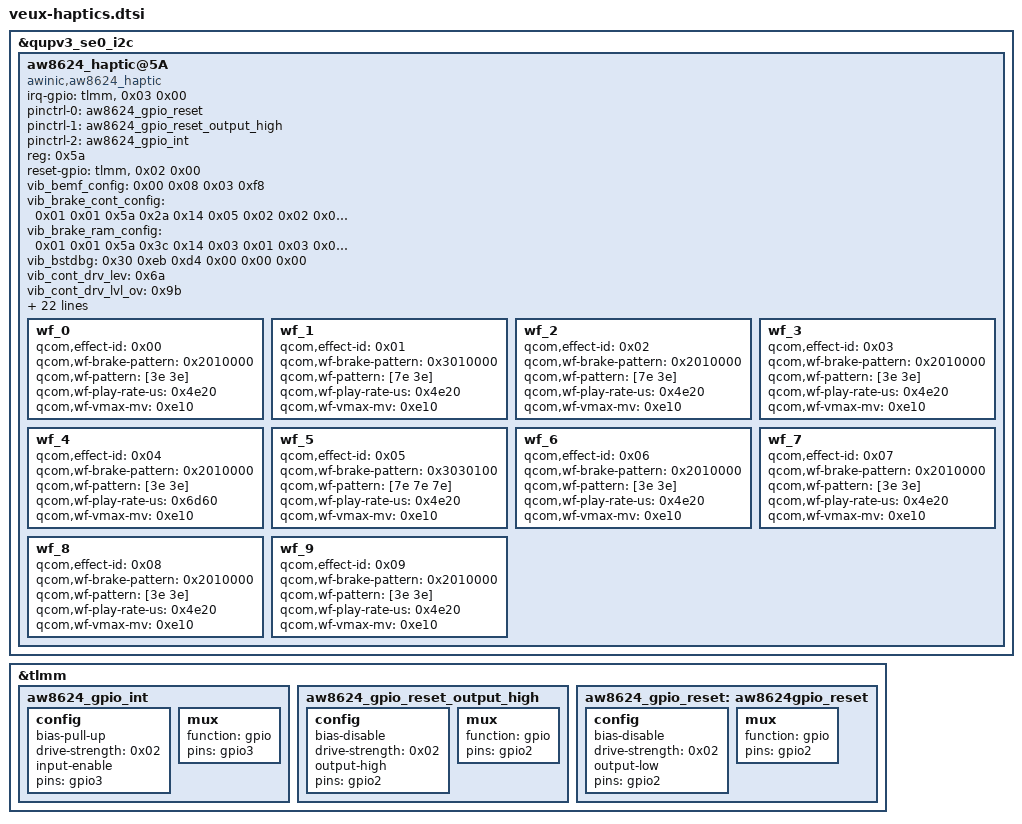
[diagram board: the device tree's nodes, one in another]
/* Xiaomi Poco X4 Pro 5G (veux) - Haptics Subsystem */

/* Fragment 49 -> &qupv3_se0_i2c */
&qupv3_se0_i2c {
	status = "ok";

	/* AWINIC AW8624 high-voltage LRA haptic motor driver at I2C address 0x5a */
		aw8624_haptic@5A {
		compatible = "awinic,aw8624_haptic";
		irq-gpio = <&tlmm>, <0x03 0x00>;
		pinctrl-0 = <&aw8624_gpio_reset>;
		pinctrl-1 = <&aw8624_gpio_reset_output_high>;
		pinctrl-2 = <&aw8624_gpio_int>;
		pinctrl-names = "aw8624_reset_reset", "aw8624_reset_active", "aw8624_interrupt_active";
		reg = <0x5a>;
		reset-gpio = <&tlmm>, <0x02 0x00>;
		vib_bemf_config = <0x00 0x08 0x03 0xf8>;
		vib_brake_cont_config = <0x01 0x01 0x5a 0x2a 0x14 0x05 0x02 0x02 0x00 0x00 0x00 0x00 0x00 0x00 0x00 0x00 0x00 0x00 0x00 0x00 0x00 0x00 0x00 0x00>;
		vib_brake_ram_config = <0x01 0x01 0x5a 0x3c 0x14 0x03 0x01 0x03 0x01 0x01 0x5a 0x3c 0x1e 0x05 0x01 0x03 0x00 0x00 0x32 0x28 0x19 0x00 0x05 0x03>;
		vib_bstdbg = <0x30 0xeb 0xd4 0x00 0x00 0x00>;
		vib_cont_drv_lev = <0x6a>;
		vib_cont_drv_lvl_ov = <0x9b>;
		vib_cont_num_brk = <0x03>;
		vib_cont_td = <0xf06c>;
		vib_cont_zc_thr = <0x8f8>;
		vib_duration_time = <0x0f 0x3c 0x00 0x00 0x00>;
		vib_effect_id_boundary = <0x0a>;
		vib_effect_max = <0x209>;
		vib_f0_cali_percen = <0x07>;
		vib_f0_coeff = <0x104>;
		vib_f0_pre = <0x802>;
		vib_f0_trace_parameter = <0x09 0x05 0x01 0x0f>;
		vib_func_parameter1 = <0x01>;
		vib_gain_flag = <0x01>;
		vib_r_spare = <0x68>;
		vib_rtp_time = <0x14 0x14 0x14 0x14 0x14 0x14 0x14 0x14 0x14 0x1e 0x28 0x32 0x3c 0x46 0x50 0x5a 0x64 0x6e 0x78 0x82 0x8c 0x96 0xa0 0xaa 0xb4 0xbe 0xc8 0xd2 0xdc 0xe6 0xf0 0xfa 0x104 0x10e 0x118 0x122 0x12c 0x136 0x140 0x14a 0x14 0x14 0x14 0x14 0x14 0x14 0x14 0x14 0x14 0x14 0x14 0x14 0x14 0x14 0x14 0x14 0x14 0x14 0x14 0x14 0x14 0x14 0x14 0x14 0x14 0x14 0x14 0x14 0x14 0x14 0x14 0x14 0x14 0x14 0x14 0x14 0x14 0x14 0x14 0x14 0x14 0x14 0x14 0x14 0x14 0x14 0x14 0x14 0x14 0x14 0x14 0x14 0x14 0x14 0x14 0x14 0x14 0x14 0x14 0x14 0x14 0x14 0x14 0x14 0x14 0x14 0x14 0x14 0x14 0x14 0x14 0x14 0x14 0x14 0x14 0x14 0x14 0x14 0x14 0x14 0x14 0x14 0x14 0x14 0x14 0x14 0x14 0x14 0x14 0x14 0x14 0x14 0x14 0x14 0x14 0x14 0x14 0x14 0x14 0x14 0x14 0x14 0x14 0x14 0x14 0x14 0x14 0x14 0x14 0x14 0x14 0x14 0x14 0x14 0x14 0x14 0x14 0x14 0x14 0x14 0x14 0x14 0x14 0x14 0x14 0x14 0x14 0x14 0x14 0x14 0x14 0x14 0x14 0x14 0x14>;
		vib_sw_brake = <0x2c>;
		vib_td_brake = <0xa6e0 0xa6e0 0xa6e0>;
		vib_tset = <0x11>;
		vib_wavloop = <0x00 0x06 0x01 0x0f 0x00 0x00 0x00 0x00 0x00 0x00>;
		vib_wavseq = <0x00 0x01 0x01 0x02 0x00 0x00 0x00 0x00 0x00 0x00 0x00 0x00 0x00 0x00 0x00 0x00>;

		wf_0 {
			qcom,effect-id = <0x00>;
			qcom,wf-brake-pattern = <0x2010000>;
			qcom,wf-pattern = [3e 3e];
			qcom,wf-play-rate-us = <0x4e20>;
			qcom,wf-vmax-mv = <0xe10>;
		};

		wf_1 {
			qcom,effect-id = <0x01>;
			qcom,wf-brake-pattern = <0x3010000>;
			qcom,wf-pattern = [7e 3e];
			qcom,wf-play-rate-us = <0x4e20>;
			qcom,wf-vmax-mv = <0xe10>;
		};

		wf_2 {
			qcom,effect-id = <0x02>;
			qcom,wf-brake-pattern = <0x2010000>;
			qcom,wf-pattern = [7e 3e];
			qcom,wf-play-rate-us = <0x4e20>;
			qcom,wf-vmax-mv = <0xe10>;
		};

		wf_3 {
			qcom,effect-id = <0x03>;
			qcom,wf-brake-pattern = <0x2010000>;
			qcom,wf-pattern = [3e 3e];
			qcom,wf-play-rate-us = <0x4e20>;
			qcom,wf-vmax-mv = <0xe10>;
		};

		wf_4 {
			qcom,effect-id = <0x04>;
			qcom,wf-brake-pattern = <0x2010000>;
			qcom,wf-pattern = [3e 3e];
			qcom,wf-play-rate-us = <0x6d60>;
			qcom,wf-vmax-mv = <0xe10>;
		};

		wf_5 {
			qcom,effect-id = <0x05>;
			qcom,wf-brake-pattern = <0x3030100>;
			qcom,wf-pattern = [7e 7e 7e];
			qcom,wf-play-rate-us = <0x4e20>;
			qcom,wf-vmax-mv = <0xe10>;
		};

		wf_6 {
			qcom,effect-id = <0x06>;
			qcom,wf-brake-pattern = <0x2010000>;
			qcom,wf-pattern = [3e 3e];
			qcom,wf-play-rate-us = <0x4e20>;
			qcom,wf-vmax-mv = <0xe10>;
		};

		wf_7 {
			qcom,effect-id = <0x07>;
			qcom,wf-brake-pattern = <0x2010000>;
			qcom,wf-pattern = [3e 3e];
			qcom,wf-play-rate-us = <0x4e20>;
			qcom,wf-vmax-mv = <0xe10>;
		};

		wf_8 {
			qcom,effect-id = <0x08>;
			qcom,wf-brake-pattern = <0x2010000>;
			qcom,wf-pattern = [3e 3e];
			qcom,wf-play-rate-us = <0x4e20>;
			qcom,wf-vmax-mv = <0xe10>;
		};

		wf_9 {
			qcom,effect-id = <0x09>;
			qcom,wf-brake-pattern = <0x2010000>;
			qcom,wf-pattern = [3e 3e];
			qcom,wf-play-rate-us = <0x4e20>;
			qcom,wf-vmax-mv = <0xe10>;
		};
	};
};

/* Fragment 50 -> &tlmm */
&tlmm {

	aw8624_gpio_int: aw8624_gpio_int {

		config {
			bias-pull-up;
			drive-strength = <0x02>;
			input-enable;
			pins = "gpio3";
		};

		mux {
			function = "gpio";
			pins = "gpio3";
		};
	};

	aw8624_gpio_reset_output_high: aw8624_gpio_reset_output_high {

		config {
			bias-disable;
			drive-strength = <0x02>;
			output-high;
			pins = "gpio2";
		};

		mux {
			function = "gpio";
			pins = "gpio2";
		};
	};

	aw8624_gpio_reset: aw8624gpio_reset {

		config {
			bias-disable;
			drive-strength = <0x02>;
			output-low;
			pins = "gpio2";
		};

		mux {
			function = "gpio";
			pins = "gpio2";
		};
	};
};
